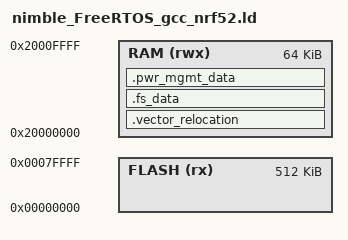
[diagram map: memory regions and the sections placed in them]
/* Linker script to configure memory regions. */

SEARCH_DIR(.)
GROUP(-lgcc -lc -lnosys)

MEMORY
{
  FLASH (rx) : ORIGIN = 0x0, LENGTH = 0x80000
  RAM (rwx) :  ORIGIN = 0x20000000, LENGTH = 0x10000
}

SECTIONS
{
  .vector_relocation :
  {
    . = ALIGN(256);
    __vector_tbl_reloc__ = .;
    . = . + (__isr_vector_end - __isr_vector_start);
    . = ALIGN(256);
  } > RAM
  .fs_data :
  {
    PROVIDE(__start_fs_data = .);
    KEEP(*(.fs_data))
    PROVIDE(__stop_fs_data = .);
  } > RAM
  .pwr_mgmt_data :
  {
    PROVIDE(__start_pwr_mgmt_data = .);
    KEEP(*(.pwr_mgmt_data))
    PROVIDE(__stop_pwr_mgmt_data = .);
  } > RAM
} INSERT AFTER .data;

INCLUDE "nrf5x_common.ld"
